# soc_ic_secure register map
Vendor: Texas Instruments
Peripheral module from a debugger description file (folder CC35X1).
Registers are 32-bit, access per field, no defined reset value unless marked. A register's access mark holds for its fields unless they carry their own. Offsets are as the file gives them; lines under a group give offsets from that group; [hi:lo] are bit positions; {n}, {i} and the like mark numbered series; 'fields as' and 'values as' point back to an identical list; <NAME> marks a mode.

## soc_ic_secure
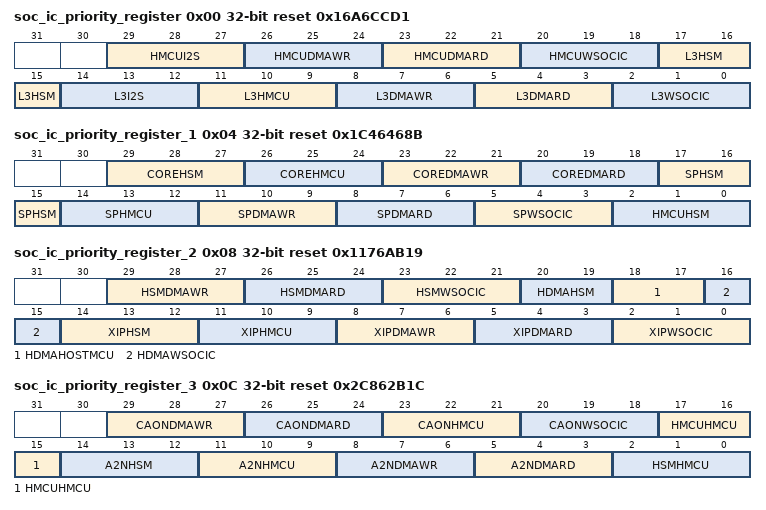
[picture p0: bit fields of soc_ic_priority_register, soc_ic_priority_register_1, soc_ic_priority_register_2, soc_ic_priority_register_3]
0x00 soc_ic_priority_register reset 0x16A6CCD1 — SOC Interconnect priority registers. Define the priority in which master will be arbitered toward each slave.
  [29:27] HMCUI2S rw — <Slave-name><Master-name> Set the priority for specific Master transaction toward a specific slave. priority values: 0 - N.A 1 - Lowest priority 2 - Higher priority 3- ... N - Highest priority where N is NUM_OF_MASTERS
  [26:24] HMCUDMAWR rw — <Slave-name><Master-name> Set the priority for specific Master transaction toward a specific slave. priority values: 0 - N.A 1 - Lowest priority 2 - Higher priority 3- ... N - Highest priority where N is NUM_OF_MASTERS
  [23:21] HMCUDMARD rw — <Slave-name><Master-name> Set the priority for specific Master transaction toward a specific slave. priority values: 0 - N.A 1 - Lowest priority 2 - Higher priority 3- ... N - Highest priority where N is NUM_OF_MASTERS
  [20:18] HMCUWSOCIC rw — <Slave-name><Master-name> Set the priority for specific Master transaction toward a specific slave. priority values: 0 - N.A 1 - Lowest priority 2 - Higher priority 3- ... N - Highest priority where N is NUM_OF_MASTERS
  [17:15] L3HSM rw — <Slave-name><Master-name> Set the priority for specific Master transaction toward a specific slave. priority values: 0 - N.A 1 - Lowest priority 2 - Higher priority 3- ... N - Highest priority where N is NUM_OF_MASTERS
  [14:12] L3I2S rw — <Slave-name><Master-name> Set the priority for specific Master transaction toward a specific slave. priority values: 0 - N.A 1 - Lowest priority 2 - Higher priority 3- ... N - Highest priority where N is NUM_OF_MASTERS
  [11:9] L3HMCU rw — <Slave-name><Master-name> Set the priority for specific Master transaction toward a specific slave. priority values: 0 - N.A 1 - Lowest priority 2 - Higher priority 3- ... N - Highest priority where N is NUM_OF_MASTERS
  [8:6] L3DMAWR rw — <Slave-name><Master-name> Set the priority for specific Master transaction toward a specific slave. priority values: 0 - N.A 1 - Lowest priority 2 - Higher priority 3- ... N - Highest priority where N is NUM_OF_MASTERS
  [5:3] L3DMARD rw — <Slave-name><Master-name> Set the priority for specific Master transaction toward a specific slave. priority values: 0 - N.A 1 - Lowest priority 2 - Higher priority 3- ... N - Highest priority where N is NUM_OF_MASTERS
  [2:0] L3WSOCIC rw — <Slave-name><Master-name> Set the priority for specific Master transaction toward a specific slave. priority values: 0 - N.A 1 - Lowest priority 2 - Higher priority 3- ... N - Highest priority where N is NUM_OF_MASTERS
0x04 soc_ic_priority_register_1 reset 0x1C46468B — SOC Interconnect priority registers. Define the priority in which master will be arbitered toward each slave.
  [29:27] COREHSM rw — <Slave-name><Master-name> Set the priority for specific Master transaction toward a specific slave. priority values: 0 - N.A 1 - Lowest priority 2 - Higher priority 3- ... N - Highest priority where N is NUM_OF_MASTERS
  [26:24] COREHMCU rw — <Slave-name><Master-name> Set the priority for specific Master transaction toward a specific slave. priority values: 0 - N.A 1 - Lowest priority 2 - Higher priority 3- ... N - Highest priority where N is NUM_OF_MASTERS
  [23:21] COREDMAWR rw — <Slave-name><Master-name> Set the priority for specific Master transaction toward a specific slave. priority values: 0 - N.A 1 - Lowest priority 2 - Higher priority 3- ... N - Highest priority where N is NUM_OF_MASTERS
  [20:18] COREDMARD rw — <Slave-name><Master-name> Set the priority for specific Master transaction toward a specific slave. priority values: 0 - N.A 1 - Lowest priority 2 - Higher priority 3- ... N - Highest priority where N is NUM_OF_MASTERS
  [17:15] SPHSM rw — <Slave-name><Master-name> Set the priority for specific Master transaction toward a specific slave. priority values: 0 - N.A 1 - Lowest priority 2 - Higher priority 3- ... N - Highest priority where N is NUM_OF_MASTERS
  [14:12] SPHMCU rw — <Slave-name><Master-name> Set the priority for specific Master transaction toward a specific slave. priority values: 0 - N.A 1 - Lowest priority 2 - Higher priority 3- ... N - Highest priority where N is NUM_OF_MASTERS
  [11:9] SPDMAWR rw — <Slave-name><Master-name> Set the priority for specific Master transaction toward a specific slave. priority values: 0 - N.A 1 - Lowest priority 2 - Higher priority 3- ... N - Highest priority where N is NUM_OF_MASTERS
  [8:6] SPDMARD rw — <Slave-name><Master-name> Set the priority for specific Master transaction toward a specific slave. priority values: 0 - N.A 1 - Lowest priority 2 - Higher priority 3- ... N - Highest priority where N is NUM_OF_MASTERS
  [5:3] SPWSOCIC rw — <Slave-name><Master-name> Set the priority for specific Master transaction toward a specific slave. priority values: 0 - N.A 1 - Lowest priority 2 - Higher priority 3- ... N - Highest priority where N is NUM_OF_MASTERS
  [2:0] HMCUHSM rw — <Slave-name><Master-name> Set the priority for specific Master transaction toward a specific slave. priority values: 0 - N.A 1 - Lowest priority 2 - Higher priority 3- ... N - Highest priority where N is NUM_OF_MASTERS
0x08 soc_ic_priority_register_2 reset 0x1176AB19 — SOC Interconnect priority registers. Define the priority in which master will be arbitered toward each slave.
  [29:27] HSMDMAWR rw — <Slave-name><Master-name> Set the priority for specific Master transaction toward a specific slave. priority values: 0 - N.A 1 - Lowest priority 2 - Higher priority 3- ... N - Highest priority where N is NUM_OF_MASTERS
  [26:24] HSMDMARD rw — <Slave-name><Master-name> Set the priority for specific Master transaction toward a specific slave. priority values: 0 - N.A 1 - Lowest priority 2 - Higher priority 3- ... N - Highest priority where N is NUM_OF_MASTERS
  [23:21] HSMWSOCIC rw — <Slave-name><Master-name> Set the priority for specific Master transaction toward a specific slave. priority values: 0 - N.A 1 - Lowest priority 2 - Higher priority 3- ... N - Highest priority where N is NUM_OF_MASTERS
  [20:19] HDMAHSM rw — <Slave-name><Master-name> Set the priority for specific Master transaction toward a specific slave. priority values: 0 - N.A 1 - Lowest priority 2 - Higher priority 3- ... N - Highest priority where N is NUM_OF_MASTERS
  [18:17] HDMAHOSTMCU rw — <Slave-name><Master-name> Set the priority for specific Master transaction toward a specific slave. priority values: 0 - N.A 1 - Lowest priority 2 - Higher priority 3- ... N - Highest priority where N is NUM_OF_MASTERS
  [16:15] HDMAWSOCIC rw — <Slave-name><Master-name> Set the priority for specific Master transaction toward a specific slave. priority values: 0 - N.A 1 - Lowest priority 2 - Higher priority 3- ... N - Highest priority where N is NUM_OF_MASTERS
  [14:12] XIPHSM rw — <Slave-name><Master-name> Set the priority for specific Master transaction toward a specific slave. priority values: 0 - N.A 1 - Lowest priority 2 - Higher priority 3- ... N - Highest priority where N is NUM_OF_MASTERS
  [11:9] XIPHMCU rw — <Slave-name><Master-name> Set the priority for specific Master transaction toward a specific slave. priority values: 0 - N.A 1 - Lowest priority 2 - Higher priority 3- ... N - Highest priority where N is NUM_OF_MASTERS
  [8:6] XIPDMAWR rw — <Slave-name><Master-name> Set the priority for specific Master transaction toward a specific slave. priority values: 0 - N.A 1 - Lowest priority 2 - Higher priority 3- ... N - Highest priority where N is NUM_OF_MASTERS
  [5:3] XIPDMARD rw — <Slave-name><Master-name> Set the priority for specific Master transaction toward a specific slave. priority values: 0 - N.A 1 - Lowest priority 2 - Higher priority 3- ... N - Highest priority where N is NUM_OF_MASTERS
  [2:0] XIPWSOCIC rw — <Slave-name><Master-name> Set the priority for specific Master transaction toward a specific slave. priority values: 0 - N.A 1 - Lowest priority 2 - Higher priority 3- ... N - Highest priority where N is NUM_OF_MASTERS
0x0C soc_ic_priority_register_3 reset 0x2C862B1C — SOC Interconnect priority registers. Define the priority in which master will be arbitered toward each slave.
  [29:27] CAONDMAWR rw — <Slave-name><Master-name> Set the priority for specific Master transaction toward a specific slave. priority values: 0 - N.A 1 - Lowest priority 2 - Higher priority 3- ... N - Highest priority where N is NUM_OF_MASTERS
  [26:24] CAONDMARD rw — <Slave-name><Master-name> Set the priority for specific Master transaction toward a specific slave. priority values: 0 - N.A 1 - Lowest priority 2 - Higher priority 3- ... N - Highest priority where N is NUM_OF_MASTERS
  [23:21] CAONHMCU rw — <Slave-name><Master-name> Set the priority for specific Master transaction toward a specific slave. priority values: 0 - N.A 1 - Lowest priority 2 - Higher priority 3- ... N - Highest priority where N is NUM_OF_MASTERS
  [20:18] CAONWSOCIC rw — <Slave-name><Master-name> Set the priority for specific Master transaction toward a specific slave. priority values: 0 - N.A 1 - Lowest priority 2 - Higher priority 3- ... N - Highest priority where N is NUM_OF_MASTERS
  [17:15] HMCUHMCU rw — <Slave-name><Master-name> Set the priority for specific Master transaction toward a specific slave. priority values: 0 - N.A 1 - Lowest priority 2 - Higher priority 3- ... N - Highest priority where N is NUM_OF_MASTERS
  [14:12] A2NHSM rw — <Slave-name><Master-name> Set the priority for specific Master transaction toward a specific slave. priority values: 0 - N.A 1 - Lowest priority 2 - Higher priority 3- ... N - Highest priority where N is NUM_OF_MASTERS
  [11:9] A2NHMCU rw — <Slave-name><Master-name> Set the priority for specific Master transaction toward a specific slave. priority values: 0 - N.A 1 - Lowest priority 2 - Higher priority 3- ... N - Highest priority where N is NUM_OF_MASTERS
  [8:6] A2NDMAWR rw — <Slave-name><Master-name> Set the priority for specific Master transaction toward a specific slave. priority values: 0 - N.A 1 - Lowest priority 2 - Higher priority 3- ... N - Highest priority where N is NUM_OF_MASTERS
  [5:3] A2NDMARD rw — <Slave-name><Master-name> Set the priority for specific Master transaction toward a specific slave. priority values: 0 - N.A 1 - Lowest priority 2 - Higher priority 3- ... N - Highest priority where N is NUM_OF_MASTERS
  [2:0] HSMHMCU rw — <Slave-name><Master-name> Set the priority for specific Master transaction toward a specific slave. priority values: 0 - N.A 1 - Lowest priority 2 - Higher priority 3- ... N - Highest priority where N is NUM_OF_MASTERS
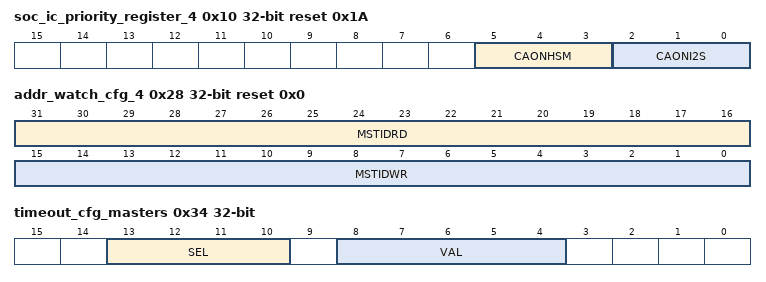
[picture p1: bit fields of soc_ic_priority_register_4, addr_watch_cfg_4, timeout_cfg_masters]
0x10 soc_ic_priority_register_4 reset 0x1A — SOC Interconnect priority registers. Define the priority in which master will be arbitered toward each slave.
  [5:3] CAONHSM rw — <Slave-name><Master-name> Set the priority for specific Master transaction toward a specific slave. priority values: 0 - N.A 1 - Lowest priority 2 - Higher priority 3- ... N - Highest priority where N is NUM_OF_MASTERS
  [2:0] CAONI2S rw — <Slave-name><Master-name> Set the priority for specific Master transaction toward a specific slave. priority values: 0 - N.A 1 - Lowest priority 2 - Higher priority 3- ... N - Highest priority where N is NUM_OF_MASTERS
0x14 ocp_slave_serror_and_timeout_1_status rw — OCP Slave serror and Time-out Status 1. status bits when ocp slave response with serror clear on write sticky - catch the first error, until register is cleared to 0
  [31:0] STA1 — status bits when ocp slave response with serror clear on write sticky - catch the first error, until register is cleared to 0 [31:0] - maddr *note - can only clear on write to 32'b0 writing 1 byte will clear all 4 bytes
0x18 ocp_slave_serror_and_timeout_2_status — OCP Slave serror and Time-out Status 2.
  [9:0] STA2 rw — status bits when ocp slave response with serror or timeout: clear on write sticky - catch the first error, until register is cleared to 0 for serror and timeout handeling: [9:6] cause [5:4] mcmd - command type: 2=RD ; 1=WR [3:0] masterid cause mapping: 0 - masters 1 - core aon 2 - hsm 3 - host xip 4 - host dma 5 - host mcu 6 - shared periph 7 - app2nab 8 - core wsocic 9 - l3 slaves if cuase is 'masters' - masterid mapped as it mapped in [TOMSTCFG.SEL]. else - masterid mapping: 0 - M33NS 1 - M33S 6 - Core (wsoc_ic) 8 - I2S/HSM M33NS access 9 - I2S/HSM M33S access 10 - I2S/HSM Core access 12 - DMA M33NS access 13 - DMA M33S access 14 - DMA Core access *note - can only clear on write to 10'b0 writing 1 byte will clear all 2 bytes
0x1C addr_watch_cfg_1 reset 0x0 — Address Watch Configuration 1.
  [3:0] SEL rw — select which slave port of ocp_ic is checked in address-watch: 0 - core_aon 1 - hsm 2 - host_xip_cfg 3 - host_dma 4 - host_mcu 5 - shared_periph (all shared peripheral I2C,UART,I2S,SDMMC,SPI,CAN,PDM,GPTIMERS,AFA,ADC,SDIO) 6 - app2nab 7 - core_wsocic 8 - all l3 peripherals under bridge (COEX,IOMUX,PRCM,SCRTCHPAD,PRCM_AON,CKM,FUSE_FARM,GPADC_CTRL,DEBUGSS, SOC_IC,SOC_AON_SECURED/NON_SECURED,RTC,OCLA,MEMSS_GLOBALPORT,HOST_AON,SYSREASOURCES,SYSTIMER)
0x20 addr_watch_cfg_2 rw reset 0x0 — Address Watch Configuration 2.
  [31:0] LOW — lower maddr threshold for address-watch addr_hit = (maddr >= thr_low) & (maddr <= thr_high)
0x24 addr_watch_cfg_3 rw reset 0x0 — Address Watch Configuration 3.
  [31:0] HIGH — upper maddr threshold for address-watch addr_hit = (maddr >= thr_low) & (maddr <= thr_high)
0x28 addr_watch_cfg_4 rw reset 0x0 — Address Watch Configuration 4.
  [31:16] MSTIDRD — each bit enables check on MCMD=RD per MASTERID for example value of 0x0120 will enable check of masterid=5 and masterid=8 if check_wr=0x0000 and check_rd=0x0000 then the clock for address-watch is disabled locally to save power
  [15:0] MSTIDWR — each bit enables check on MCMD=WR per MASTERID for example value of 0x0120 will enable check of masterid=5 and masterid=8 if check_wr=0x0000 and check_rd=0x0000 then the clock for address-watch is disabled locally to save power
0x2C addr_watch_status_1 rw — Address Watch Status 1.
  [31:0] STA1 — keep when hit - Clear on Write [31:0] - maddr
0x30 addr_watch_status_2 — Address Watch Status 2.
  [4:0] STA2 rw — keep when hit - Clear on Write [4] - command type: 0=RD ; 1=WR [3:0] - masterid masterid mapping: 0 - M33NS 1 - M33S 6 - Core (wsoc_ic) 8 - I2S/HSM M33NS access 9 - I2S/HSM M33S access 10 - I2S/HSM Core access 12 - DMA M33NS access 13 - DMA M33S access 14 - DMA Core access
0x34 timeout_cfg_masters — Time-out Masters Configuration.
  [13:10] SEL rw — select master for timeout by masterid. masterid 2 MSBs are fixed, 2 LSBs defined in [SOC_AON:PROTENUM.*] register. { '00' , [SOC_AON:PROTENUM.M33NSEC]} - M33NS { '00' , [SOC_AON:PROTENUM.M33SEC]} - M33S { '01' , [SOC_AON:PROTENUM.CORE]} - Core (wsoc_ic) { '10' , [SOC_AON:PROTENUM.M33NSEC]} - I2S/HSM M33NS access { '10' , [SOC_AON:PROTENUM.M33SEC]} - I2S/HSM M33S access { '10' , [SOC_AON:PROTENUM.CORE]} - I2S/HSM Core access { '11' , [SOC_AON:PROTENUM.M33NSEC]} - DMA M33NS access { '11' , [SOC_AON:PROTENUM.M33SEC]} - DMA M33S access { '11' , [SOC_AON:PROTENUM.CORE]} - DMA Core access
  [8:4] VAL rw — value for timeout for all slaves: valid value - 0x0- 0x1F if value is 0 timeout feature is disabled for all slaves Granulation is double word (64b): 1 - means 16 clocks period, 2 - means 32 clocks period... in h/w the value in FIELD is shifted left 4 times (x16). example: 0x08 => 0x80 (8 means 128)
0x38 timeout_cfg_slv — Time-out Slave Configuration.
  [8:4] VAL rw — value for timeout for all slaves: valid value - 0x0- 0x1F if value is 0 timeout feature is disabled for all slaves Granulation is double word (64b): 1 - means 16 clocks period, 2 - means 32 clocks period... in h/w the value in FIELD is shifted left 4 times (x16). example: 0x08 => 0x80 (8 means 128)
